AUTOSAR XML (schema 00046)
package /VehicleProject
  system System
    system mapping System_MPPNG
      data-mappings:
        {data-element=SG_Sig_Grp_0x210.SG_Sig_Grp_0x210, signal-group=SG_Sig_Grp_0x210, type-mapping=sender-rec-record-type-mapping=record-element-mappings=[{implementation-record-element=F_Led1_State, system-signal=F_Led1_State}, {implementation-record-element=F_Led2_State, system-signal=F_Led2_State}, {implementation-record-element=F_Led3_State, system-signal=F_Led3_State}, {implementation-record-element=F_Led4_State, system-signal=F_Led4_State}]}
        {data-element=SG_Sig_Grp_0x211.SG_Sig_Grp_0x211, signal-group=SG_Sig_Grp_0x211, type-mapping=sender-rec-record-type-mapping=record-element-mappings=[{implementation-record-element=F_Button1_State, system-signal=F_Button1_State}, {implementation-record-element=F_Button2_State, system-signal=F_Button2_State}, {implementation-record-element=F_Button3_State, system-signal=F_Button3_State}, {implementation-record-element=F_Button4_State, system-signal=F_Button4_State}]}
        {data-element=SG_Sig_Grp_0x212.SG_Sig_Grp_0x212, signal-group=SG_Sig_Grp_0x212, type-mapping=sender-rec-record-type-mapping=record-element-mappings=[{implementation-record-element=F_PowerMode, system-signal=F_PowerMode}, {implementation-record-element=SupF_Checksum_0x212, system-signal=SupF_Checksum_0x212}, {implementation-record-element=SupF_Counter_0x212, system-signal=SupF_Counter_0x212}]}
        {data-element=SG_Sig_Grp_0x213.SG_Sig_Grp_0x213, signal-group=SG_Sig_Grp_0x213, type-mapping=sender-rec-record-type-mapping=sender-rec-record-element-mapping{implementation-record-element=F_AAA_Angle, system-signal=F_AAA_Angle}}
        {data-element=SG_Sig_Grp_0x214.SG_Sig_Grp_0x214, signal-group=SG_Sig_Grp_0x214, type-mapping=sender-rec-record-type-mapping=record-element-mappings=[{implementation-record-element=F_Sig_0x214_Used_1, system-signal=F_Sig_0x214_Used_1}, {implementation-record-element=F_Sig_0x214_Used_2, system-signal=F_Sig_0x214_Used_2}, {implementation-record-element=F_Sig_0x214_Used_3, system-signal=F_Sig_0x214_Used_3}, {implementation-record-element=F_Sig_0x214_Used_5, system-signal=F_Sig_0x214_Used_5}]}
        {data-element=SG_Sig_Grp_0x216.SG_Sig_Grp_0x216, signal-group=SG_Sig_Grp_0x216, type-mapping=sender-rec-record-type-mapping=record-element-mappings=[{implementation-record-element=F_Meg_E2E_Error, system-signal=F_Meg_E2E_Error}, {implementation-record-element=F_Mes_Lost_Error, system-signal=F_Mes_Lost_Error}]}
        {data-element=SG_Sig_Grp_0x300.SG_Sig_Grp_0x300, signal-group=SG_Sig_Grp_0x300, type-mapping=sender-rec-record-type-mapping=record-element-mappings=[{implementation-record-element=D_Led1_Control, system-signal=D_Led1_Control}, {implementation-record-element=D_Led2_Control, system-signal=D_Led2_Control}, {implementation-record-element=D_Led3_Control, system-signal=D_Led3_Control}, {implementation-record-element=D_Led4_Control, system-signal=D_Led4_Control}, {implementation-record-element=SupD_Checksum_0x300, system-signal=SupD_Checksum_0x300}, {implementation-record-element=SupD_Counter_0x300, system-signal=SupD_Counter_0x300}]}
        {data-element=SG_Sig_Grp_0x301.SG_Sig_Grp_0x301, signal-group=SG_Sig_Grp_0x301, type-mapping=sender-rec-record-type-mapping=record-element-mappings=[{implementation-record-element=D_Button1_Control, system-signal=D_Button1_Control}, {implementation-record-element=D_Button2_Control, system-signal=D_Button2_Control}, {implementation-record-element=D_Button3_Control, system-signal=D_Button3_Control}, {implementation-record-element=D_Button4_Control, system-signal=D_Button4_Control}]}
        {data-element=SG_Sig_Grp_0x302.SG_Sig_Grp_0x302, signal-group=SG_Sig_Grp_0x302, type-mapping=sender-rec-record-type-mapping=record-element-mappings=[{implementation-record-element=E_Sig_0x302_Used_1, system-signal=E_Sig_0x302_Used_1}, {implementation-record-element=E_Sig_0x302_Used_2, system-signal=E_Sig_0x302_Used_2}, {implementation-record-element=E_Sig_0x302_Used_3, system-signal=E_Sig_0x302_Used_3}]}
        {data-element=SG_Sig_Grp_0x304.SG_Sig_Grp_0x304, signal-group=SG_Sig_Grp_0x304, type-mapping=sender-rec-record-type-mapping=record-element-mappings=[{implementation-record-element=D_Led1_CtrlMode, system-signal=D_Led1_CtrlMode}, {implementation-record-element=D_Led2_CtrlMode, system-signal=D_Led2_CtrlMode}, {implementation-record-element=D_Led3_CtrlMode, system-signal=D_Led3_CtrlMode}, {implementation-record-element=D_Led4_CtrlMode, system-signal=D_Led4_CtrlMode}, {implementation-record-element=SupD_Checksum_0x304, system-signal=SupD_Checksum_0x304}, {implementation-record-element=SupD_Counter_0x304, system-signal=SupD_Counter_0x304}]}
    root-software-compositions:
      root sw composition prototype EcuSwComposition: software-composition=ECU_Composition
package /ECUCompositionTypes
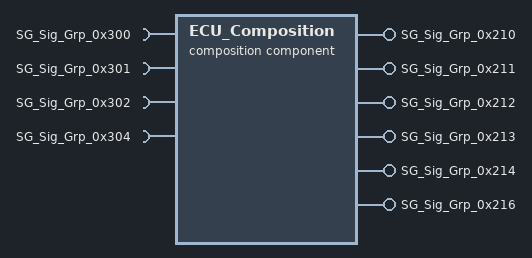
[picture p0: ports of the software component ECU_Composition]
  composition sw component type ECU_Composition
    6 x provide port:
      SG_Sig_Grp_0x210: nonqueued-sender-com-spec{data-element=SG_Sig_Grp_0x210, init-value=fields=[F_Led1_State:0, F_Led2_State:0, F_Led3_State:0, F_Led4_State:0]}, provided-interface=SG_Sig_Grp_0x210
      SG_Sig_Grp_0x211: nonqueued-sender-com-spec{data-element=SG_Sig_Grp_0x211, init-value=fields=[F_Button1_State:0, F_Button2_State:0, F_Button3_State:0, F_Button4_State:0]}, provided-interface=SG_Sig_Grp_0x211
      SG_Sig_Grp_0x212: nonqueued-sender-com-spec{data-element=SG_Sig_Grp_0x212, init-value=fields=[F_PowerMode:0, SupF_Checksum_0x212:0, SupF_Counter_0x212:0]}, provided-interface=SG_Sig_Grp_0x212
      SG_Sig_Grp_0x213: nonqueued-sender-com-spec{data-element=SG_Sig_Grp_0x213, init-value=fields=F_AAA_Angle:36}, provided-interface=SG_Sig_Grp_0x213
      SG_Sig_Grp_0x214: nonqueued-sender-com-spec{data-element=SG_Sig_Grp_0x214, init-value=fields=[F_Sig_0x214_Used_1:0, F_Sig_0x214_Used_2:0, F_Sig_0x214_Used_3:0, F_Sig_0x214_Used_5:0]}, provided-interface=SG_Sig_Grp_0x214
      SG_Sig_Grp_0x216: nonqueued-sender-com-spec{data-element=SG_Sig_Grp_0x216, init-value=fields=[F_Meg_E2E_Error:0, F_Mes_Lost_Error:0]}, provided-interface=SG_Sig_Grp_0x216
    4 x require port:
      SG_Sig_Grp_0x300: nonqueued-receiver-com-spec{data-element=SG_Sig_Grp_0x300, init-value=fields=[D_Led1_Control:2, D_Led2_Control:2, D_Led3_Control:2, D_Led4_Control:2, SupD_Checksum_0x300:0, SupD_Counter_0x300:0]}, required-interface=SG_Sig_Grp_0x300
      SG_Sig_Grp_0x301: nonqueued-receiver-com-spec{data-element=SG_Sig_Grp_0x301, init-value=fields=[D_Button1_Control:0, D_Button2_Control:0, D_Button3_Control:0, D_Button4_Control:0]}, required-interface=SG_Sig_Grp_0x301
      SG_Sig_Grp_0x302: nonqueued-receiver-com-spec{data-element=SG_Sig_Grp_0x302, init-value=fields=[E_Sig_0x302_Used_1:0, E_Sig_0x302_Used_2:0, E_Sig_0x302_Used_3:0]}, required-interface=SG_Sig_Grp_0x302
      SG_Sig_Grp_0x304: nonqueued-receiver-com-spec{data-element=SG_Sig_Grp_0x304, init-value=fields=[D_Led1_CtrlMode:0, D_Led2_CtrlMode:0, D_Led3_CtrlMode:0, D_Led4_CtrlMode:0, SupD_Checksum_0x304:0, SupD_Counter_0x304:0]}, required-interface=SG_Sig_Grp_0x304
    10 x component:
      AppCtrl: type=AppCtrl
      AppComTx: type=AppComTx
      AppComRx: type=AppComRx
      AppWakeUpCtrl: type=AppWakeUpCtrl
      AppButtonCtrl: type=AppButtonCtrl
      AppLedCtrl: type=AppLedCtrl
      IoHwAb: type=IoHwAb
      AppCtrl2: type=AppCtrl2
      AppCtrl1: type=AppCtrl1
      IcuCdd: type=IcuCdd
    connect IoHwAb.IoHwAbCS_LED{1..4} -> AppLedCtrl.IoHwAbCS_LED{1..4}
    connect IoHwAb.IoHwAbCS_KL15 -> AppLedCtrl.IoHwAbCS_KL15
    connect IoHwAb.IoHwAbCS_KL15 -> AppButtonCtrl.IoHwAbCS_KL15
    connect IoHwAb.IoHwAbCS_Button1 -> AppButtonCtrl.IoHwAbCS_Button1
    connect IoHwAb.IoHwAbCS_Button3 -> AppButtonCtrl.IoHwAbCS_Button3
    connect IoHwAb.IoHwAbCS_Button4 -> AppButtonCtrl.IoHwAbCS_Button4
    connect IoHwAb.IoHwAbCS_Button2 -> AppButtonCtrl.IoHwAbCS_Button2
    connect IoHwAb.IoHwAbCS_KL15 -> AppWakeUpCtrl.IoHwAbCS_KL15
    connect IoHwAb.IoHwAbCS_KL15 -> AppCtrl.IoHwAbCS_KL15
    connect IoHwAb.IoHwAbCS_Button1 -> IcuCdd.IoHwAbCS_Button1
    delegate AppComRx.SG_Sig_Grp_0x{300..302} <-> outer port SG_Sig_Grp_0x{300..302}
    delegate AppComRx.SG_Sig_Grp_0x304 <-> outer port SG_Sig_Grp_0x304
    connect AppComRx.SG_Sig_Grp_0x{300..302}_SR_S -> AppCtrl.SG_Sig_Grp_0x{300..302}_SR_S
    connect AppComRx.SG_Sig_Grp_0x304_SR_S -> AppCtrl.SG_Sig_Grp_0x304_SR_S
    delegate AppComTx.SG_Sig_Grp_0x{210..214} <-> outer port SG_Sig_Grp_0x{210..214}
    delegate AppComTx.SG_Sig_Grp_0x216 <-> outer port SG_Sig_Grp_0x216
    connect AppCtrl.SG_Sig_Grp_0x210_SR_S -> AppComTx.SG_Sig_Grp_0x210_SR_R
    connect AppCtrl.SG_Sig_Grp_0x{211..214}_SR_R -> AppComTx.SG_Sig_Grp_0x{211..214}_SR_R
    connect AppCtrl.SG_Sig_Grp_0x216_SR_R -> AppComTx.SG_Sig_Grp_0x216_SR_R
    connect AppCtrl.Meg_Trigger_State_0x214_SR_S -> AppComTx.Meg_Trigger_State_0x214_SR_R
package /EndToEndProtections
  end to end protection set EndToEndProtectionSet
    end to end protection ECU_Composition_SG_Sig_Grp_0x400_SG_Sig_Grp_0x400: end-to-end-profile={category=PROFILE_01, data-ids=13124, data-id-mode=0, data-length=64, max-delta-counter-init=2, crc-offset=0, counter-offset=56, max-no-new-or-repeated-data=15, sync-counter-init=1, data-id-nibble-offset=0}, end-to-end-protection-variable-prototype=receiver=EcuSwComposition.SG_Sig_Grp_0x400
    end to end protection ECU_Composition_SG_Sig_Grp_0x112_SG_Sig_Grp_0x112: end-to-end-profile={category=PROFILE_01, data-ids=4386, data-id-mode=0, data-length=64, max-delta-counter-init=2, crc-offset=0, counter-offset=56, max-no-new-or-repeated-data=15, sync-counter-init=1, data-id-nibble-offset=0}, end-to-end-protection-variable-prototype=EcuSwComposition.SG_Sig_Grp_0x112
